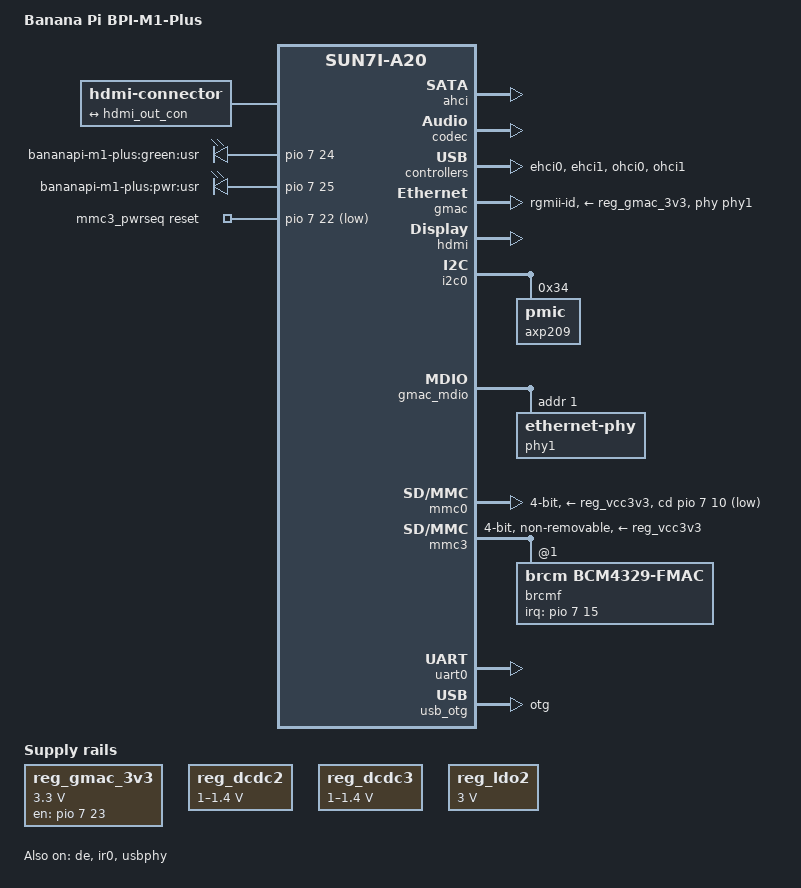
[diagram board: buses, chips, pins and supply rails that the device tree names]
/dts-v1/;
#include "sun7i-a20.dtsi"
#include "sunxi-common-regulators.dtsi"
#include <dt-bindings/gpio/gpio.h>
#include <dt-bindings/interrupt-controller/arm-gic.h>
/ {
	model = "Banana Pi BPI-M1-Plus";
	compatible = "sinovoip,bpi-m1-plus", "allwinner,sun7i-a20";
	aliases {
		serial0 = &uart0;
	};
	chosen {
		stdout-path = "serial0:115200n8";
	};
	hdmi-connector {
		compatible = "hdmi-connector";
		type = "a";
		port {
			hdmi_con_in: endpoint {
				remote-endpoint = <&hdmi_out_con>;
			};
		};
	};
	leds {
		compatible = "gpio-leds";
		led-0 {
			label = "bananapi-m1-plus:green:usr";
			gpios = <&pio 7 24 GPIO_ACTIVE_HIGH>;
		};
		led-1 {
			label = "bananapi-m1-plus:pwr:usr";
			gpios = <&pio 7 25 GPIO_ACTIVE_HIGH>;
			default-state = "on";
		};
	};
	mmc3_pwrseq: mmc3_pwrseq {
		compatible = "mmc-pwrseq-simple";
		reset-gpios = <&pio 7 22 GPIO_ACTIVE_LOW>;  
	};
	reg_gmac_3v3: gmac-3v3 {
		compatible = "regulator-fixed";
		regulator-name = "gmac-3v3";
		regulator-min-microvolt = <3300000>;
		regulator-max-microvolt = <3300000>;
		startup-delay-us = <100000>;
		enable-active-high;
		gpio = <&pio 7 23 GPIO_ACTIVE_HIGH>;
	};
};
&ahci {
	status = "okay";
};
&codec {
	status = "okay";
};
&cpu0 {
	cpu-supply = <&reg_dcdc2>;
};
&de {
	status = "okay";
};
&ehci0 {
	status = "okay";
};
&ehci1 {
	status = "okay";
};
&gmac {
	pinctrl-names = "default";
	pinctrl-0 = <&gmac_rgmii_pins>;
	phy-handle = <&phy1>;
	phy-mode = "rgmii-id";
	phy-supply = <&reg_gmac_3v3>;
	status = "okay";
};
&hdmi {
	status = "okay";
};
&hdmi_out {
	hdmi_out_con: endpoint {
		remote-endpoint = <&hdmi_con_in>;
	};
};
&i2c0 {
	status = "okay";
	axp209: pmic@34 {
		reg = <0x34>;
		interrupt-parent = <&nmi_intc>;
		interrupts = <0 IRQ_TYPE_LEVEL_LOW>;
	};
};
#include "axp209.dtsi"
&ac_power_supply {
	status = "okay";
};
&ir0 {
	pinctrl-names = "default";
	pinctrl-0 = <&ir0_rx_pin>;
	status = "okay";
};
&gmac_mdio {
	phy1: ethernet-phy@1 {
		reg = <1>;
	};
};
&mmc0 {
	vmmc-supply = <&reg_vcc3v3>;
	bus-width = <4>;
	cd-gpios = <&pio 7 10 GPIO_ACTIVE_LOW>;  
	status = "okay";
};
&mmc3 {
	#address-cells = <1>;
	#size-cells = <0>;
	vmmc-supply = <&reg_vcc3v3>;
	mmc-pwrseq = <&mmc3_pwrseq>;
	bus-width = <4>;
	non-removable;
	wakeup-source;
	status = "okay";
	brcmf: wifi@1 {
		reg = <1>;
		compatible = "brcm,bcm4329-fmac";
		interrupt-parent = <&pio>;
		interrupts = <7 15 IRQ_TYPE_LEVEL_LOW>;
		interrupt-names = "host-wake";
	};
};
&ohci0 {
	status = "okay";
};
&ohci1 {
	status = "okay";
};
&otg_sram {
	status = "okay";
};
&reg_dcdc2 {
	regulator-always-on;
	regulator-min-microvolt = <1000000>;
	regulator-max-microvolt = <1400000>;
	regulator-name = "vdd-cpu";
};
&reg_dcdc3 {
	regulator-always-on;
	regulator-min-microvolt = <1000000>;
	regulator-max-microvolt = <1400000>;
	regulator-name = "vdd-int-dll";
};
&reg_ldo1 {
	regulator-name = "vdd-rtc";
};
&reg_ldo2 {
	regulator-always-on;
	regulator-min-microvolt = <3000000>;
	regulator-max-microvolt = <3000000>;
	regulator-name = "avcc";
};
&reg_usb0_vbus {
	status = "okay";
};
&uart0 {
	pinctrl-names = "default";
	pinctrl-0 = <&uart0_pb_pins>;
	status = "okay";
};
&usb_otg {
	dr_mode = "otg";
	status = "okay";
};
&usb_power_supply {
	status = "okay";
};
&usbphy {
	usb0_id_det-gpios = <&pio 7 4 GPIO_ACTIVE_HIGH>;  
	usb0_vbus_power-supply = <&usb_power_supply>;
	usb0_vbus-supply = <&reg_usb0_vbus>;
	status = "okay";
};
